AUTOSAR XML (schema 4-2-1)
standard types defined: uint8
package /DataTypes
  impl type Uint8_T: category=VALUE, base-type=uint8, range phys 0..255, raw 0..255
package /Interfaces
  client server interface CS_LedControl_I
    operation Switch_LedState: possible-error=E_LED_FAILED
      arg LedState: type=Uint8_T, direction=IN
    error E_LED_FAILED: error-code=1
  sender receiver interface SR_DoorState_I
    data DoorState: type=Uint8_T, init-value=0
package /SWCs
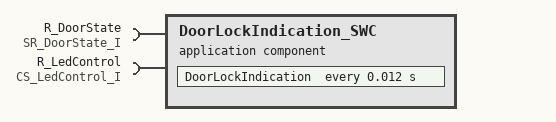
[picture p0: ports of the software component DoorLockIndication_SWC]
  application sw component type DoorLockIndication_SWC
    require port R_DoorState: required-interface=SR_DoorState_I
    require port R_LedControl: required-interface=CS_LedControl_I
    behavior DoorLockIndication_IB
      timing event TE_DoorLockIndication_12ms: start-on-event=DoorLockIndication, period=0.012
      runnable DoorLockIndication: symbol=DoorLockIndication_Run
        data-read-access:
          access DRA_SwitchLedState: accessed-variable=R_DoorState.DoorState
        sync call SCP_SwitchLedState: operation=R_LedControl.Switch_LedState
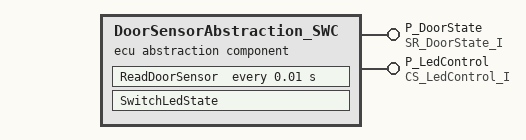
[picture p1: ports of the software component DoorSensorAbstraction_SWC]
  ecu abstraction sw component type DoorSensorAbstraction_SWC
    provide port P_DoorState: provided-interface=SR_DoorState_I
    provide port P_LedControl: provided-interface=CS_LedControl_I
    behavior DoorSensorAbstraction_IB
      timing event TE_ReadDoorSensor_10ms: start-on-event=ReadDoorSensor, period=0.01
      operation invoked event OIE_SwitchLedState: start-on-event=SwitchLedState, operation=P_LedControl.Switch_LedState
      runnable ReadDoorSensor: symbol=ReadDoorSensor_Run
        data-write-access:
          access VA_DoorState_Write: accessed-variable=P_DoorState.DoorState
      runnable SwitchLedState: symbol=SwitchLedState_Run
package /Compositions
  composition sw component type DoorLockSystem_Comp
    component DoorLockIndication_Instance: type=DoorLockIndication_SWC
    component DoorSensorAbstraction_Instance: type=DoorSensorAbstraction_SWC
    connect DoorSensorAbstraction_Instance.P_DoorState -> DoorLockIndication_Instance.R_DoorState
    connect DoorSensorAbstraction_Instance.P_LedControl -> DoorLockIndication_Instance.R_LedControl
